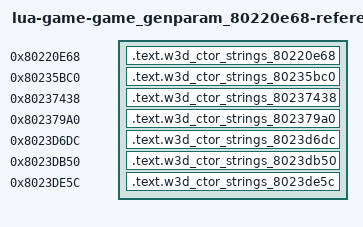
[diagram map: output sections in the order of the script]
/* Generated reference-only placements. All bodies are source-built. */
OUTPUT_FORMAT("elf32-powerpc")
OUTPUT_ARCH(powerpc)
ENTRY(w3d_ctor_strings_80220e68)
_SDA_BASE_ = 0x804b2540;
_SDA2_BASE_ = 0x804c2540;
fn_801ea0ec = 0x801ea0ec;
fn_8020c5c0 = 0x8020c5c0;
fn_8021ef08 = 0x8021ef08;
fn_8023b59c = 0x8023b59c;
fn_8023d32c = 0x8023d32c;
fn_8023d574 = 0x8023d574;
fn_80341884 = 0x80341884;
lbl_804b06a0 = 0x804b06a0;
w3d_vtable_8041a528 = 0x8041a528;
w3d_vtable_8041a720 = 0x8041a720;
w3d_vtable_8041a770 = 0x8041a770;
w3d_vtable_8041a8d8 = 0x8041a8d8;
w3d_vtable_8041ab58 = 0x8041ab58;
w3d_vtable_8041ab80 = 0x8041ab80;
w3d_vtable_8041abd0 = 0x8041abd0;
SECTIONS {
  .text.w3d_ctor_strings_80220e68 0x80220e68 : { *(.text.w3d_ctor_strings_80220e68) }
  .text.w3d_ctor_strings_80235bc0 0x80235bc0 : { *(.text.w3d_ctor_strings_80235bc0) }
  .text.w3d_ctor_strings_80237438 0x80237438 : { *(.text.w3d_ctor_strings_80237438) }
  .text.w3d_ctor_strings_802379a0 0x802379a0 : { *(.text.w3d_ctor_strings_802379a0) }
  .text.w3d_ctor_strings_8023d6dc 0x8023d6dc : { *(.text.w3d_ctor_strings_8023d6dc) }
  .text.w3d_ctor_strings_8023db50 0x8023db50 : { *(.text.w3d_ctor_strings_8023db50) }
  .text.w3d_ctor_strings_8023de5c 0x8023de5c : { *(.text.w3d_ctor_strings_8023de5c) }
  /DISCARD/ : { *(.text*) *(.rodata*) *(.data*) *(.bss*) *(.sdata*) *(.sbss*) *(.comment) }
}
